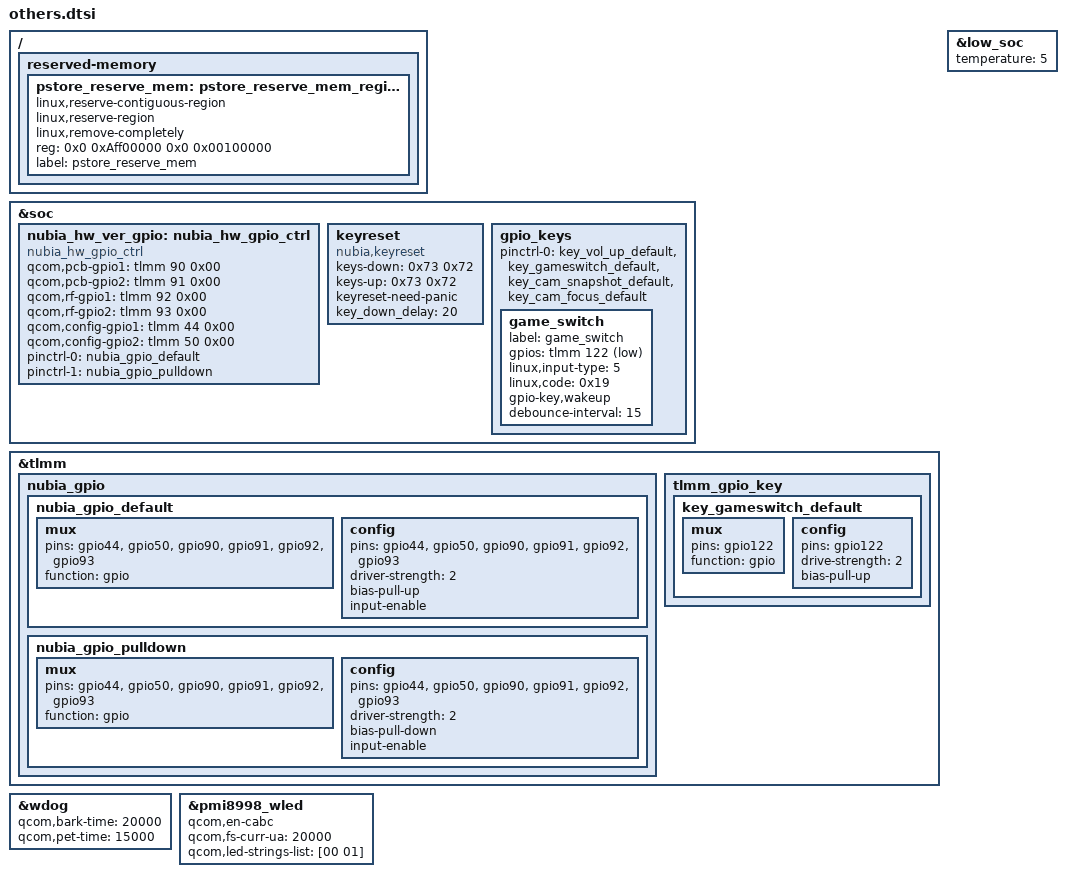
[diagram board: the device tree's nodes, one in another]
/*
 * nubia overwrite dts
 */
 &soc {
	nubia_hw_ver_gpio: nubia_hw_gpio_ctrl {
		compatible = "nubia_hw_gpio_ctrl";
		qcom,pcb-gpio1 = <&tlmm 90 0x00>;
		qcom,pcb-gpio2 = <&tlmm 91 0x00>;
		qcom,rf-gpio1 = <&tlmm 92 0x00>;
		qcom,rf-gpio2 = <&tlmm 93 0x00>;
		qcom,config-gpio1 = <&tlmm 44 0x00>;
		qcom,config-gpio2 = <&tlmm 50 0x00>;
		pinctrl-names = "pull_up_default","pull_down_default";
		pinctrl-0 = <&nubia_gpio_default>;
		pinctrl-1 = <&nubia_gpio_pulldown>;
	};

    keyreset {
        compatible = "nubia,keyreset";
        keys-down = <0x73 0x72>;
        keys-up = <0x73 0x72>;
        keyreset-need-panic;
        key_down_delay = <20>;
	};

	gpio_keys {
		pinctrl-0 = <&key_vol_up_default
			     &key_gameswitch_default
			     &key_cam_snapshot_default
			     &key_cam_focus_default>;

		game_switch {
			label = "game_switch";
			gpios = <&tlmm  122 0x1>;
			linux,input-type = <5>;
			linux,code = <0x19>;
			gpio-key,wakeup;
			debounce-interval = <15>;
		};
	};
};
&tlmm {
	nubia_gpio {
		nubia_gpio_default: nubia_gpio_default {
			mux {
				pins = "gpio44", "gpio50", "gpio90", "gpio91", "gpio92", "gpio93";
				function = "gpio";
			};
			config {
				pins = "gpio44", "gpio50", "gpio90", "gpio91", "gpio92", "gpio93";
				driver-strength = <2>; /* 2mA */
				bias-pull-up;
				input-enable;
			};
		};

		nubia_gpio_pulldown: nubia_gpio_pulldown {
			mux {
				pins = "gpio44", "gpio50", "gpio90", "gpio91", "gpio92", "gpio93";
				function = "gpio";
			};
			config {
				pins = "gpio44", "gpio50", "gpio90", "gpio91", "gpio92", "gpio93";
				driver-strength = <2>; /* 2mA */
				bias-pull-down;
				input-enable;
			};
		};
	};

	tlmm_gpio_key {
        key_gameswitch_default: key_gameswitch_default {
                mux {
                        pins =  "gpio122";
                        function = "gpio";
                };

                config {
                        pins =  "gpio122";
                        drive-strength = <2>;
                        bias-pull-up;
                };
         };
    };
};

/* pstore mem*/
/ {
	reserved-memory {
		pstore_reserve_mem: pstore_reserve_mem_region@0 {
			linux,reserve-contiguous-region;
			linux,reserve-region;
			linux,remove-completely;
			reg = <0x0 0xAff00000 0x0 0x00100000>;
			label = "pstore_reserve_mem";
		};
	};
};

&wdog {
	qcom,bark-time = <20000>;
	qcom,pet-time = <15000>;
};

&low_soc {
        temperature = <5>;
};
&pmi8998_wled {
	qcom,en-cabc;
	qcom,fs-curr-ua = <20000>;
	qcom,led-strings-list = [00 01];
};
